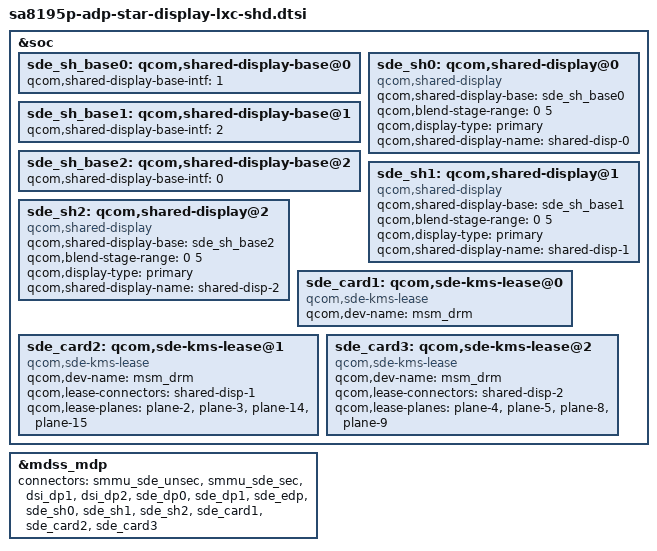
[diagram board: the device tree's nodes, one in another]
&soc {
	sde_sh_base0: qcom,shared-display-base@0 {
		qcom,shared-display-base-intf = <1>;
	};

	sde_sh_base1: qcom,shared-display-base@1 {
		qcom,shared-display-base-intf = <2>;
	};

	sde_sh_base2: qcom,shared-display-base@2 {
		qcom,shared-display-base-intf = <0>;
	};

	sde_sh0: qcom,shared-display@0 {
		compatible = "qcom,shared-display";
		qcom,shared-display-base = <&sde_sh_base0>;
		qcom,blend-stage-range = <0 5>;
		qcom,display-type = "primary";
		qcom,shared-display-name = "shared-disp-0";
	};

	sde_sh1: qcom,shared-display@1 {
		compatible = "qcom,shared-display";
		qcom,shared-display-base = <&sde_sh_base1>;
		qcom,blend-stage-range = <0 5>;
		qcom,display-type = "primary";
		qcom,shared-display-name = "shared-disp-1";
	};

	sde_sh2: qcom,shared-display@2 {
		compatible = "qcom,shared-display";
		qcom,shared-display-base = <&sde_sh_base2>;
		qcom,blend-stage-range = <0 5>;
		qcom,display-type = "primary";
		qcom,shared-display-name = "shared-disp-2";
	};

	sde_card1: qcom,sde-kms-lease@0 {
		compatible = "qcom,sde-kms-lease";
		qcom,dev-name = "msm_drm";
	};

	sde_card2: qcom,sde-kms-lease@1 {
		compatible = "qcom,sde-kms-lease";
		qcom,dev-name = "msm_drm";
		qcom,lease-connectors = "shared-disp-1";
		qcom,lease-planes = "plane-2", "plane-3",
			"plane-14", "plane-15";
	};

	sde_card3: qcom,sde-kms-lease@2 {
		compatible = "qcom,sde-kms-lease";
		qcom,dev-name = "msm_drm";
		qcom,lease-connectors = "shared-disp-2";
		qcom,lease-planes = "plane-4", "plane-5",
			"plane-8", "plane-9";
	};
};

&mdss_mdp {
	connectors = <&smmu_sde_unsec &smmu_sde_sec &dsi_dp1 &dsi_dp2
			&sde_dp0 &sde_dp1 &sde_edp
			&sde_sh0 &sde_sh1 &sde_sh2
			&sde_card1 &sde_card2 &sde_card3>;
};
